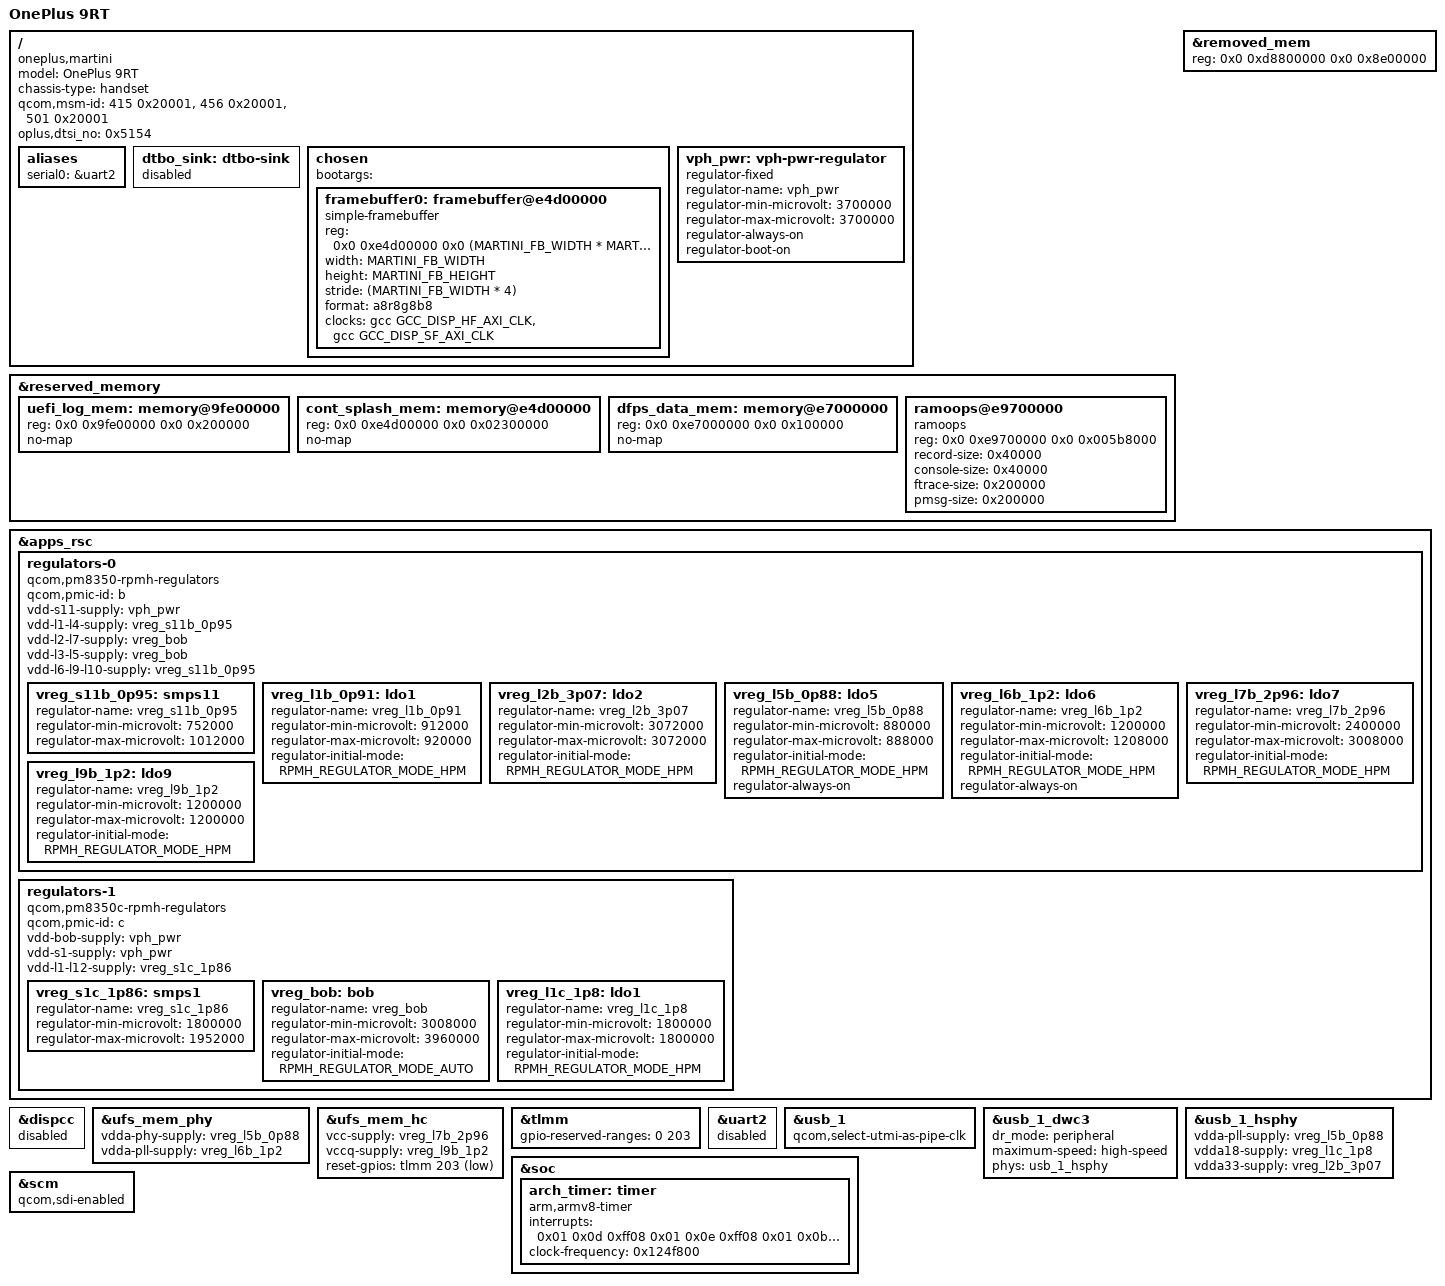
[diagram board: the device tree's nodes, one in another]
// SPDX-License-Identifier: BSD-3-Clause
/*
 * OnePlus 9RT (oneplus,martini / oplus project 20820), SM8350 "lahaina".
 *
 * Minimal mainline bring-up device tree:
 *   - hands the bootloader's continuous-splash framebuffer to simpledrm so the
 *     kernel log becomes visible on the panel (there is no UART access),
 *   - reserves every firmware carve-out the vendor device tree reserves, with
 *     the martini-specific overrides applied,
 *   - sets up ramoops in the same region the vendor kernel uses, so the console
 *     log can be recovered from Android after a reboot.
 *
 * Nothing that touches the display hardware is enabled: &mdss and &dispcc are
 * both disabled on purpose so the panel keeps scanning out what the bootloader
 * left. Note that a deferred probe is NOT enough for that -- see &dispcc below.
 */

/dts-v1/;

#include <dt-bindings/gpio/gpio.h>
#include <dt-bindings/input/input.h>
#include <dt-bindings/regulator/qcom,rpmh-regulator.h>
#include "sm8350.dtsi"
#include "pm8350.dtsi"
#include "pm8350b.dtsi"
#include "pm8350c.dtsi"

/* Panel: 6.62" 1080x2400 AMOLED, single DSI. */
#define MARTINI_FB_WIDTH	1080
#define MARTINI_FB_HEIGHT	2400

/ {
	model = "OnePlus 9RT";
	compatible = "oneplus,martini", "qcom,sm8350";
	chassis-type = "handset";

	/*
	 * ABL matches this against the SoC ID it reads from SMEM before it
	 * accepts a device tree. Copied verbatim from the root of the DTB the
	 * bootloader actually handed to Android (/sys/firmware/fdt): SoC IDs
	 * 415/456/501 at revision v2.1.
	 *
	 * qcom,board-id is deliberately absent. The vendor base DTB that ABL
	 * accepted (androidboot.dtb_idx=0) carries no board-id either — that
	 * property only lives in the dtbo overlays — and supplying one that
	 * does not match the board ID in SMEM makes ABL reject the DTB outright.
	 */
	qcom,msm-id = <415 0x20001>, <456 0x20001>, <501 0x20001>;

	/*
	 * oplus's own addition to ABL's device tree selection: the project number
	 * from SMEM, which ABL also passes on as androidboot.prjname=20820.
	 * 0x5154 = 20820 = martini.
	 *
	 * Probably not actually required — the vendor base DTB ABL selected
	 * (androidboot.dtb_idx=0) lists <0x4d71 0x4d67 0x5176 0x2085a>, which does
	 * not contain 0x5154 at all, and had ABL been matching on this property it
	 * would have picked entry 3 instead. But it costs nothing, it is the right
	 * value for this device, and having it here means our tree differs from the
	 * known-good vendor one in the *value* of this property rather than in
	 * whether it exists — a distinction a patched selector could plausibly care
	 * about, and one no other test we have would isolate.
	 */
	oplus,dtsi_no = <0x5154>;

	aliases {
		serial0 = &uart2;
	};

	/*
	 * ABL refuses to boot a device tree it cannot apply the stock dtbo overlay
	 * to, and that overlay resolves 158 vendor labels that do not exist in a
	 * mainline tree. Replacing the dtbo with a no-op one does not work either:
	 * ABL rejects hand-built overlays even on the vendor tree.
	 *
	 * So this node exists purely as a landing area. A post-processing step
	 * (martini/mksink.py) rewrites __symbols__ so every label the overlay
	 * looks for resolves here, which makes the overlay apply cleanly while all
	 * of its vendor content ends up inside one disabled node that no mainline
	 * driver will ever look at. Nothing in this device tree references it.
	 */
	dtbo_sink: dtbo-sink {
		status = "disabled";
	};

	chosen {
		#address-cells = <2>;
		#size-cells = <2>;
		ranges;

		/*
		 * No stdout-path on purpose. It would only take effect if the
		 * command line carried no console= at all: of_console_check()
		 * bails out on console_set_on_cmdline, and CONFIG_CMDLINE_FORCE
		 * always gives us console=tty0. So it never selected a console
		 * here, and pointing it at a disabled node is just misleading.
		 */

		/*
		 * ABL appends its own androidboot.* arguments to whatever is
		 * already in bootargs rather than creating the property, so it
		 * has to exist. The contents are irrelevant to us: the kernel is
		 * built with CONFIG_CMDLINE_FORCE, so it uses its built-in
		 * command line and ignores this entirely.
		 */
		bootargs = "";

		/*
		 * Continuous splash buffer left running by XBL/ABL. The base
		 * address is the martini override of splash_memory from
		 * martini-common.dtsi. The generic lahaina value (0xe1000000)
		 * is NOT usable here: it falls inside martini's enlarged
		 * removed_mem carve-out below, so touching it trips an XPU
		 * violation and the SoC resets straight back into fastboot.
		 *
		 * Only the GCC display AXI clocks are held. The dispcc clocks
		 * are deliberately not referenced, and &dispcc itself is
		 * disabled below -- deferring its probe is not enough to keep
		 * it away from the panel.
		 */
		framebuffer0: framebuffer@e4d00000 {
			compatible = "simple-framebuffer";
			reg = <0x0 0xe4d00000 0x0
			       (MARTINI_FB_WIDTH * MARTINI_FB_HEIGHT * 4)>;
			width = <MARTINI_FB_WIDTH>;
			height = <MARTINI_FB_HEIGHT>;
			stride = <(MARTINI_FB_WIDTH * 4)>;
			format = "a8r8g8b8";

			clocks = <&gcc GCC_DISP_HF_AXI_CLK>,
				 <&gcc GCC_DISP_SF_AXI_CLK>;
		};
	};

	/*
	 * Battery rail. Every SMPS on both PMICs is fed from it, and the RPMh
	 * regulator driver wants a parent supply for each rail it registers, so
	 * it has to be modelled -- as a fixed regulator, because nothing in
	 * Linux can control it.
	 */
	vph_pwr: vph-pwr-regulator {
		compatible = "regulator-fixed";
		regulator-name = "vph_pwr";
		regulator-min-microvolt = <3700000>;
		regulator-max-microvolt = <3700000>;

		regulator-always-on;
		regulator-boot-on;
	};
};

&reserved_memory {
	/*
	 * XBL/UEFI keeps its serial log ring buffer here (oplus
	 * kboot_uboot_logmem). Reserved so the kernel never hands it out.
	 */
	uefi_log_mem: memory@9fe00000 {
		reg = <0x0 0x9fe00000 0x0 0x200000>;
		no-map;
	};

	/*
	 * Continuous splash region (martini value). Must be no-map: simpledrm
	 * ioremaps it, and the kernel must not use it as ordinary RAM or the
	 * picture turns into noise.
	 */
	cont_splash_mem: memory@e4d00000 {
		reg = <0x0 0xe4d00000 0x0 0x02300000>;
		no-map;
	};

	/* Dynamic-FPS scratch area used by the display firmware. */
	dfps_data_mem: memory@e7000000 {
		reg = <0x0 0xe7000000 0x0 0x100000>;
		no-map;
	};

	/*
	 * Same base address and zone sizes as the vendor kernel's ramoops, so
	 * the console log written here survives a reboot into Android and shows
	 * up as /sys/fs/pstore/console-ramoops there. Deliberately mappable
	 * (no no-map) because pstore has to memremap it.
	 *
	 * Do not change any of these four sizes. We are the writer and the oplus
	 * kernel is the reader, and each computes the console zone's offset from
	 * its own device tree. The vendor node (martini-common.dtsi) carves seven
	 * extra oplus zones of 0x8000 on top of ours, and the two arithmetics land
	 * on the same address only by exact coincidence:
	 *
	 *   mainline: dump = 0x5b8000 - 0x40000 - 0x200000 - 0x200000 = 0x178000,
	 *             which is 5 whole records of 0x40000 -> console at +0x140000
	 *   oplus:    dump = 0x5b8000 - ...            - 7 * 0x8000  = 0x140000,
	 *             the same 5 records                -> console at +0x140000
	 *
	 * Raising console-size to fit a more verbose boot therefore breaks reading
	 * it back twice over: the offsets diverge, and the reader would still only
	 * take the first 0x40000 of a larger ring. Cut the log volume instead.
	 *
	 * The dump zones need none of that luck: they sit at the very start of the
	 * region in both layouts (fs/pstore/ram.c:788) with the same record-size,
	 * so a panic record always reads back as /sys/fs/pstore/dmesg-ramoops-0.
	 * That is the channel the lockup detectors in build.sh aim for.
	 */
	ramoops@e9700000 {
		compatible = "ramoops";
		reg = <0x0 0xe9700000 0x0 0x005b8000>;
		record-size = <0x40000>;
		console-size = <0x40000>;
		ftrace-size = <0x200000>;
		pmsg-size = <0x200000>;
	};
};

/*
 * martini grows the TZ/fingerprint "removed" carve-out from the generic lahaina
 * 0x6800000 to 0x8e00000 (0xd8800000..0xe1600000). Mapping the extra 38 MiB as
 * ordinary RAM faults as soon as the kernel touches it.
 */
&removed_mem {
	reg = <0x0 0xd8800000 0x0 0x8e00000>;
};

/*
 * RPMh regulators. Nothing in this tree consumes them yet: they are here so the
 * USB PHYs can be enabled next, and they are the first thing that has to be
 * proven not to disturb the bootloader's display state.
 *
 * Deliberately not the full lahaina rail set. Only the rails the USB PHYs need
 * plus the group parents the driver demands for them are declared, because a
 * rail with regulator-min-microvolt == regulator-max-microvolt has that voltage
 * *written* at registration time (set_machine_constraints() in
 * drivers/regulator/core.c), so every extra rail declared here is one more
 * write into a PMIC the bootloader has already configured. Only two of the rails
 * below are in that class -- L2B (3.072 V) and L1C (1.8 V) -- and both match the
 * vendor value to the microvolt, so those writes are no-ops.
 *
 * Every voltage here was read out of the DTB the bootloader handed to Android
 * (martini-real.dtb, /soc/apps_rsc/rpmh-regulator-*, qcom,set = <3>) and agrees
 * with sm8350-mtp.dts, with one exception noted on S11B.
 *
 * Unused rails do not get switched off behind our back: qcom-rpmh-regulator.c
 * initialises vreg->enabled to -EINVAL ("unknown", line 493), and
 * regulator_late_cleanup() skips a regulator whose is_enabled() is <= 0
 * (core.c:6822). So no regulator_ignore_unused on the command line is needed.
 * What does need care is a rail an enabled *consumer* later drops -- see the
 * always-on flags below.
 */
&apps_rsc {
	regulators-0 {
		compatible = "qcom,pm8350-rpmh-regulators";
		qcom,pmic-id = "b";

		vdd-s11-supply = <&vph_pwr>;
		vdd-l1-l4-supply = <&vreg_s11b_0p95>;
		vdd-l2-l7-supply = <&vreg_bob>;
		vdd-l3-l5-supply = <&vreg_bob>;
		vdd-l6-l9-l10-supply = <&vreg_s11b_0p95>;

		/* Parent of L1B and L6B. martini allows 1.012 V, mtp says 1.000. */
		vreg_s11b_0p95: smps11 {
			regulator-name = "vreg_s11b_0p95";
			regulator-min-microvolt = <752000>;
			regulator-max-microvolt = <1012000>;
		};

		/* usb_1_qmpphy vdda-pll, once SuperSpeed is enabled. */
		vreg_l1b_0p91: ldo1 {
			regulator-name = "vreg_l1b_0p91";
			regulator-min-microvolt = <912000>;
			regulator-max-microvolt = <920000>;
			regulator-initial-mode = <RPMH_REGULATOR_MODE_HPM>;
		};

		/* usb_1_hsphy vdda33. The only consumer in the vendor tree too. */
		vreg_l2b_3p07: ldo2 {
			regulator-name = "vreg_l2b_3p07";
			regulator-min-microvolt = <3072000>;
			regulator-max-microvolt = <3072000>;
			regulator-initial-mode = <RPMH_REGULATOR_MODE_HPM>;
		};

		/*
		 * usb_1_hsphy vdda-pll -- and, per the vendor tree, mdss_dsi_phy0's
		 * vdda-0p9 as well (plus the UFS PHY, both PCIe controllers and all
		 * six CSI PHYs). The DSI PHY is what keeps the bootloader's splash on
		 * the panel, and it is not a Linux consumer, so its RPMh vote is the
		 * bootloader's. Once the USB PHY claims this rail, the USB PHY's own
		 * regulator_bulk_disable() on runtime suspend
		 * (phy-qcom-snps-femto-v2.c:474) would drop it and take the panel --
		 * and with it the only log channel -- down. always-on is the mainline
		 * equivalent of the qcom,proxy-consumer-enable the vendor node uses.
		 */
		vreg_l5b_0p88: ldo5 {
			regulator-name = "vreg_l5b_0p88";
			regulator-min-microvolt = <880000>;
			regulator-max-microvolt = <888000>;
			regulator-initial-mode = <RPMH_REGULATOR_MODE_HPM>;
			regulator-always-on;
		};

		/* Same story as L5B: usb_1_qmpphy vdda-phy, and mdss_dsi_ctrl0 vdda-1p2. */
		vreg_l6b_1p2: ldo6 {
			regulator-name = "vreg_l6b_1p2";
			regulator-min-microvolt = <1200000>;
			regulator-max-microvolt = <1208000>;
			regulator-initial-mode = <RPMH_REGULATOR_MODE_HPM>;
			regulator-always-on;
		};

		/* ufs_mem_hc vcc. Parent is vreg_bob, same group as L2B. */
		vreg_l7b_2p96: ldo7 {
			regulator-name = "vreg_l7b_2p96";
			regulator-min-microvolt = <2400000>;
			regulator-max-microvolt = <3008000>;
			regulator-initial-mode = <RPMH_REGULATOR_MODE_HPM>;
		};

		/* ufs_mem_hc vccq. Parent is vreg_s11b_0p95, same group as L6B/L10B. */
		vreg_l9b_1p2: ldo9 {
			regulator-name = "vreg_l9b_1p2";
			regulator-min-microvolt = <1200000>;
			regulator-max-microvolt = <1200000>;
			regulator-initial-mode = <RPMH_REGULATOR_MODE_HPM>;
		};
	};

	regulators-1 {
		compatible = "qcom,pm8350c-rpmh-regulators";
		qcom,pmic-id = "c";

		vdd-bob-supply = <&vph_pwr>;
		vdd-s1-supply = <&vph_pwr>;
		vdd-l1-l12-supply = <&vreg_s1c_1p86>;

		/* Parent of L1C. */
		vreg_s1c_1p86: smps1 {
			regulator-name = "vreg_s1c_1p86";
			regulator-min-microvolt = <1800000>;
			regulator-max-microvolt = <1952000>;
		};

		/* Parent of L2B and L5B. */
		vreg_bob: bob {
			regulator-name = "vreg_bob";
			regulator-min-microvolt = <3008000>;
			regulator-max-microvolt = <3960000>;
			regulator-initial-mode = <RPMH_REGULATOR_MODE_AUTO>;
		};

		/* usb_1_hsphy vdda18. The only consumer in the vendor tree too. */
		vreg_l1c_1p8: ldo1 {
			regulator-name = "vreg_l1c_1p8";
			regulator-min-microvolt = <1800000>;
			regulator-max-microvolt = <1800000>;
			regulator-initial-mode = <RPMH_REGULATOR_MODE_HPM>;
		};
	};
};

/*
 * Display clock controller. Must be *disabled*, not merely left to defer.
 *
 * dispcc's power domain is RPMHPD_MMCX (sm8350.dtsi), the display rail, and it
 * is the only enabled consumer of it: the other four -- mdss_mdp, mdss_dp,
 * mdss_dsi0, mdss_dsi1 -- are children of &mdss, which is disabled, so no
 * devices exist for them and nothing else holds MMCX up.
 *
 * platform_probe() attaches the power domain with PD_FLAG_ATTACH_POWER_ON |
 * PD_FLAG_DETACH_POWER_OFF *before* calling the driver (drivers/base/platform.c),
 * and dispcc cannot bind here because its DSI byte/pixel PLL parents live in the
 * disabled &mdss. So the probe returns -EPROBE_DEFER, really_probe() falls into
 * probe_failed (drivers/base/dd.c:764) -> device_unbind_cleanup() ->
 * dev_pm_domain_detach(dev, detach_power_off) (dd.c:603), and MMCX is powered
 * off. The panel loses its rail and goes dark, and every deferred-probe retry
 * repeats it. Deferring is exactly as fatal as binding would have been.
 *
 * Nothing here wants dispcc: the framebuffer node holds GCC display AXI clocks
 * only. Re-enable this together with &mdss and a real panel driver, never before.
 */
&dispcc {
	status = "disabled";
};

&ufs_mem_phy {
	/*
	 * Both rails are the same L5B/L6B already declared above for the USB
	 * HS PHY (regulator-always-on there), not a separate "a"-suffix PMIC --
	 * this tree only has apps_rsc regulators-0 ("b") and regulators-1 ("c"),
	 * there is no "a" node, so vreg_l*a_* never resolved to anything.
	 */
	vdda-phy-supply = <&vreg_l5b_0p88>;
	vdda-pll-supply = <&vreg_l6b_1p2>;
	status = "okay";
};

&ufs_mem_hc {
	vcc-supply = <&vreg_l7b_2p96>;
	vccq-supply = <&vreg_l9b_1p2>;

	reset-gpios = <&tlmm 203 GPIO_ACTIVE_LOW>;
	status = "okay";
};

/*
 * TLMM pins the AP must not touch.
 *
 * gpiochip_add_data() walks every line and calls the driver's get_direction()
 * on each one that is not masked out (drivers/gpio/gpiolib.c:1309), which for
 * pinctrl-msm means reading that pin's ctl register. Some TLMM pins are owned
 * by the secure world on every lahaina device, and reading one of those is an
 * XPU violation: the SoC resets instantly, with no log. That is what killed the
 * boot inside sm8350-tlmm's probe. gpio-reserved-ranges clears those lines from
 * the gpiochip's valid_mask so the walk skips them.
 *
 * Every other mainline SM8350 board sets this and the sets genuinely differ --
 * qcom's own reference boards (mtp, hdk) use <52 8>, sagami <44 4>, surface
 * duo2 <4 4>, <12 4>, <56 4>, <76 4> -- so martini's block cannot be inferred
 * from them, and the vendor tree does not carry the property at all (the
 * downstream driver never walks the pins, so it never needed it).
 *
 * So reserve all 204 for now. This tree drives no GPIO at all -- no pinctrl
 * state is requested, the framebuffer needs no pins, and &uart2 is disabled --
 * so a fully reserved chip costs nothing, and it is guaranteed to cover
 * whatever martini's real block is instead of spending boots guessing. Narrow
 * it by bisecting the range when a GPIO is actually needed (panel reset, touch).
 */
&tlmm {
	gpio-reserved-ranges = <0 203>;
};

/*
 * Debug UART. Left disabled: this device has no UART routed out, and mainline's
 * &uart2 label on SM8350 is not the SE the vendor tree calls qup_uart -- it is
 * QUPv3 SE3 (GCC_QUPV3_WRAP0_S3_CLK, qup_uart3_default_state), which sm8350.dtsi
 * itself annotates "QUP no. 3 seems to be strictly SPI-only" in the very next
 * node. Enabling it added a driver probe and a TLMM pin remux that the known-good
 * hybrid tree does not have, on a serial engine that may not even be a UART here,
 * for no observable benefit. Re-enable only together with an actual UART cable.
 */
&uart2 {
	status = "disabled";
};

/*
 * USB in device mode: the log channel this device should have had all along.
 *
 * With CONFIG_USB_G_SERIAL and CONFIG_U_SERIAL_CONSOLE the legacy serial gadget
 * registers a printk console on ttyGS0 by itself -- gserial_alloc_line() calls
 * gs_console_init() for port 0 (drivers/usb/gadget/function/u_serial.c:1330), and
 * that console carries CON_PRINTBUFFER (u_serial.c:1092), so the whole boot log
 * buffered up to the moment the gadget binds is replayed to the host. On the host
 * it appears as a CDC ACM device (use_acm defaults to true,
 * drivers/usb/gadget/legacy/serial.c:89) -- i.e. /dev/ttyACM0.
 *
 * SuperSpeed is deliberately left out for now: &usb_1_qmpphy stays disabled, so
 * this needs neither CONFIG_TYPEC (the combo PHY's orientation-switch) nor the
 * DisplayPort graph, and 480 Mbit is not the bottleneck for a console. Enabling
 * it later is: status = "okay" on &usb_1_qmpphy with vdda-phy-supply = <&vreg_l6b_1p2>
 * and vdda-pll-supply = <&vreg_l1b_0p91>, both already declared above, plus
 * dropping the three overrides below.
 */
&usb_1 {
	status = "okay";

	/*
	 * Without an SS PHY the glue must not wait for the QMP pipe clock; this
	 * makes it select UTMI as the pipe clock source instead
	 * (drivers/usb/dwc3/dwc3-qcom.c:681).
	 */
	qcom,select-utmi-as-pipe-clk;
};

&usb_1_dwc3 {
	/*
	 * "peripheral", not "otg": with dr_mode = peripheral dwc3-qcom forces
	 * QSCRATCH VBUS_VALID on at probe (dwc3-qcom.c:692), so the gadget comes up
	 * without any VBUS sensing at all. That matters here -- the vendor tree gets
	 * its VBUS state from an extcon on the EUD block (extcon = <&eud> on its
	 * ssusb@a600000), and mainline's EUD driver is only a role switch, so there
	 * is no VBUS notifier to wait for.
	 *
	 * The ports/endpoint graph inherited from sm8350.dtsi can stay as it is: it
	 * is only read to find an extcon, and only through phys[0] (drivers/usb/dwc3/
	 * core.c:2042), which is the HS PHY and has no port node.
	 */
	dr_mode = "peripheral";
	maximum-speed = "high-speed";

	phys = <&usb_1_hsphy>;
	phy-names = "usb2-phy";
};

/*
 * All three supplies are mandatory -- the driver takes them as a bulk, not
 * optionally (phy-qcom-snps-femto-v2.c:81, :597) -- and all three match the
 * vendor tree's hsphy@88e3000: vdd = L5B, vdda18 = L1C, vdda33 = L2B.
 */
&usb_1_hsphy {
	status = "okay";

	vdda-pll-supply = <&vreg_l5b_0p88>;
	vdda18-supply = <&vreg_l1c_1p8>;
	vdda33-supply = <&vreg_l2b_3p07>;
};

&soc {
	arch_timer: timer {
		compatible = "arm,armv8-timer";
		interrupts = <0x01 0x0d 0xff08 0x01 0x0e 0xff08 0x01 0x0b 0xff08 0x01 0x0c 0xff08>;
		clock-frequency = <0x124f800>;
	};
};

&scm {
	qcom,sdi-enabled;
};
